# LRFDRFE32 register map
Vendor: Texas Instruments
Registers are 32-bit, access per field, reset 0x0 unless marked. A register's access mark holds for its fields unless they carry their own. Offsets are as the file gives them; [hi:lo] are bit positions; {n}, {i} and the like mark numbered series; 'fields as' and 'values as' point back to an identical list.

## LRFDRFE32 (part 2 of 2)
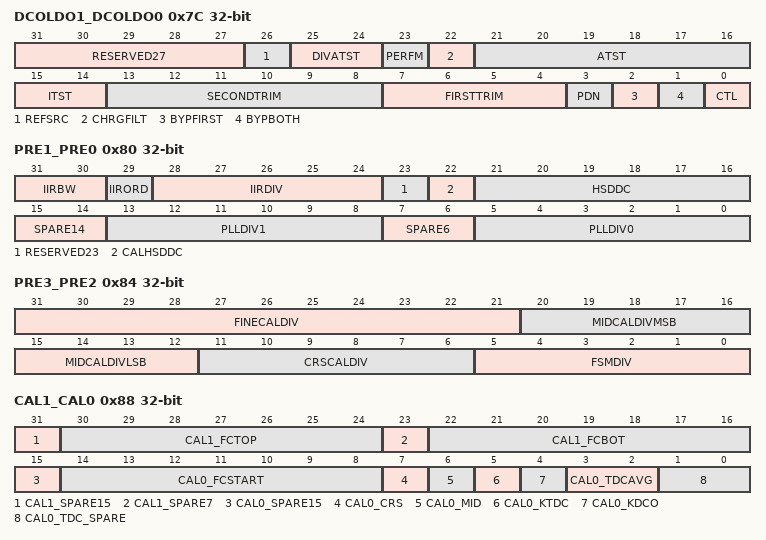
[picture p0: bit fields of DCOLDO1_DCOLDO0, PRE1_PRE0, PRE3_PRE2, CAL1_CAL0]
0x7C DCOLDO1_DCOLDO0 — Internal. Only to be used through TI provided API.
  [31:27] RESERVED27 ro — Internal. Only to be used through TI provided API.
  [26] REFSRC rw — Internal. Only to be used through TI provided API.
    1=BAW (Internal. Only to be used through TI provided API.); 0=XTAL (Internal. Only to be used through TI provided API.)
  [25:24] DIVATST rw — Internal. Only to be used through TI provided API.
    3=ONES (Internal. Only to be used through TI provided API.); 0=ZEROS (Internal. Only to be used through TI provided API.)
  [23] PERFM rw — Internal. Only to be used through TI provided API.
    1=EN (Internal. Only to be used through TI provided API.); 0=DIS (Internal. Only to be used through TI provided API.)
  [22] CHRGFILT rw — Internal. Only to be used through TI provided API.
    values as PERFM
  [21:16] ATST rw — Internal. Only to be used through TI provided API.
    32=VSSANA (Internal. Only to be used through TI provided API.); 1=FIRST_OUT (Internal. Only to be used through TI provided API.); 0=LDO_OUT (Internal. Only to be used through TI provided API.)
  [15:14] ITST rw — Internal. Only to be used through TI provided API.
    3=BOTH (Internal. Only to be used through TI provided API.); 2=SECOND (Internal. Only to be used through TI provided API.); 1=FIRST (Internal. Only to be used through TI provided API.); 0=DIS (Internal. Only to be used through TI provided API.)
  [13:8] SECONDTRIM rw — Internal. Only to be used through TI provided API.
    63=ONES (Internal. Only to be used through TI provided API.); 0=ZEROS (Internal. Only to be used through TI provided API.)
  [7:4] FIRSTTRIM rw — Internal. Only to be used through TI provided API.
    15=ONES (Internal. Only to be used through TI provided API.); 0=ZEROS (Internal. Only to be used through TI provided API.)
  [3] PDN rw — Internal. Only to be used through TI provided API.
    values as PERFM
  [2] BYPFIRST rw — Internal. Only to be used through TI provided API.
    values as PERFM
  [1] BYPBOTH rw — Internal. Only to be used through TI provided API.
    values as PERFM
  [0] CTL rw — Internal. Only to be used through TI provided API.
    values as PERFM
0x80 PRE1_PRE0 — Internal. Only to be used through TI provided API.
  [31:30] IIRBW rw — Internal. Only to be used through TI provided API.
    3=K16 (Internal. Only to be used through TI provided API.); 2=K8 (Internal. Only to be used through TI provided API.); 1=K4 (Internal. Only to be used through TI provided API.); 0=K2 (Internal. Only to be used through TI provided API.)
  [29] IIRORD rw — Internal. Only to be used through TI provided API.
    1=SECOND (Internal. Only to be used through TI provided API.); 0=FIRST (Internal. Only to be used through TI provided API.)
  [28:24] IIRDIV rw — Internal. Only to be used through TI provided API.
    31=ALLONES (Internal. Only to be used through TI provided API.); 0=ALLZEROS (Internal. Only to be used through TI provided API.)
  [23] RESERVED23 ro — Internal. Only to be used through TI provided API.
  [22] CALHSDDC rw — Internal. Only to be used through TI provided API.
    1=GATE (Internal. Only to be used through TI provided API.); 0=NOGATE (Internal. Only to be used through TI provided API.)
  [21:16] HSDDC rw — Internal. Only to be used through TI provided API.
    63=ALLONES (Internal. Only to be used through TI provided API.); 0=ALLZEROS (Internal. Only to be used through TI provided API.)
  [15:14] SPARE14 rw — Internal. Only to be used through TI provided API.
    3=ALLONES (Internal. Only to be used through TI provided API.); 0=ALLZEROS (Internal. Only to be used through TI provided API.)
  [13:8] PLLDIV1 rw — Internal. Only to be used through TI provided API.
    values as HSDDC
  [7:6] SPARE6 rw — Internal. Only to be used through TI provided API.
    values as SPARE14
  [5:0] PLLDIV0 rw — Internal. Only to be used through TI provided API.
    values as HSDDC
0x84 PRE3_PRE2 rw — Internal. Only to be used through TI provided API.
  [31:21] FINECALDIV — Internal. Only to be used through TI provided API.
    0x7FF=ALLONES (Internal. Only to be used through TI provided API.); 0=ALLZEROS (Internal. Only to be used through TI provided API.)
  [20:16] MIDCALDIVMSB — Internal. Only to be used through TI provided API.
    values as PRE1_PRE0.IIRDIV
  [15:12] MIDCALDIVLSB — Internal. Only to be used through TI provided API.
    15=ALLONES (Internal. Only to be used through TI provided API.); 0=ALLZEROS (Internal. Only to be used through TI provided API.)
  [11:6] CRSCALDIV — Internal. Only to be used through TI provided API.
    values as PRE1_PRE0.HSDDC
  [5:0] FSMDIV — Internal. Only to be used through TI provided API.
    values as PRE1_PRE0.HSDDC
0x88 CAL1_CAL0 rw — Internal. Only to be used through TI provided API.
  [31] CAL1_SPARE15 — Internal. Only to be used through TI provided API.
    1=ONE (Internal. Only to be used through TI provided API.); 0=ZERO (Internal. Only to be used through TI provided API.)
  [30:24] CAL1_FCTOP — Internal. Only to be used through TI provided API.
    127=ALLONES (Internal. Only to be used through TI provided API.); 0=ALLZEROS (Internal. Only to be used through TI provided API.)
  [23] CAL1_SPARE7 — Internal. Only to be used through TI provided API.
    values as CAL1_SPARE15
  [22:16] CAL1_FCBOT — Internal. Only to be used through TI provided API.
    values as CAL1_FCTOP
  [15] CAL0_SPARE15 — Internal. Only to be used through TI provided API.
    values as CAL1_SPARE15
  [14:8] CAL0_FCSTART — Internal. Only to be used through TI provided API.
    values as CAL1_FCTOP
  [7] CAL0_CRS — Internal. Only to be used through TI provided API.
    values as DCOLDO1_DCOLDO0.PERFM
  [6] CAL0_MID — Internal. Only to be used through TI provided API.
    values as DCOLDO1_DCOLDO0.PERFM
  [5] CAL0_KTDC — Internal. Only to be used through TI provided API.
    values as DCOLDO1_DCOLDO0.PERFM
  [4] CAL0_KDCO — Internal. Only to be used through TI provided API.
    values as DCOLDO1_DCOLDO0.PERFM
  [3:2] CAL0_TDCAVG — Internal. Only to be used through TI provided API.
    3=REPEAT_8_TIMES (Internal. Only to be used through TI provided API.); 2=REPEAT_4_TIMES (Internal. Only to be used through TI provided API.); 1=REPEAT_2_TIMES (Internal. Only to be used through TI provided API.); 0=REPEAT_1_TIME (Internal. Only to be used through TI provided API.)
  [1:0] CAL0_TDC_SPARE — Internal. Only to be used through TI provided API.
    values as PRE1_PRE0.SPARE14
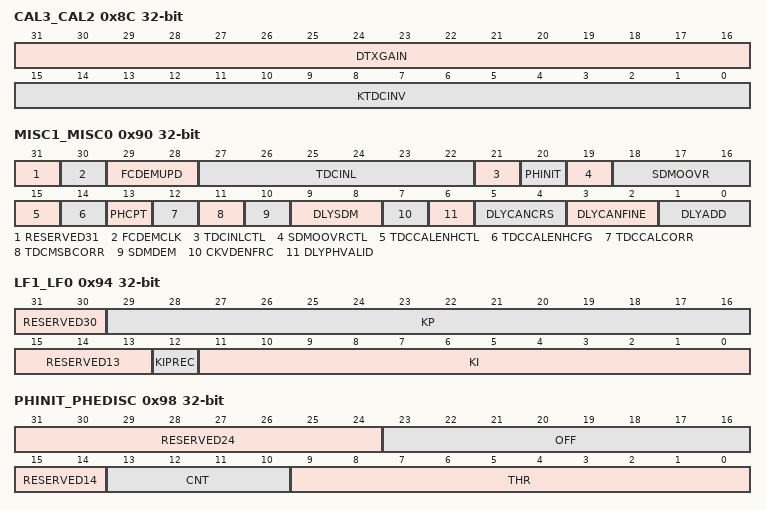
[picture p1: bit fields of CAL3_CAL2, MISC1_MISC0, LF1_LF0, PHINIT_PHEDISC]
0x8C CAL3_CAL2 rw — Internal. Only to be used through TI provided API.
  [31:16] DTXGAIN — Internal. Only to be used through TI provided API.
    0xFFFF=ALLONES (Internal. Only to be used through TI provided API.); 0=ALLZEROS (Internal. Only to be used through TI provided API.)
  [15:0] KTDCINV — Internal. Only to be used through TI provided API.
    values as DTXGAIN
0x90 MISC1_MISC0 — Internal. Only to be used through TI provided API.
  [31] RESERVED31 ro — Internal. Only to be used through TI provided API.
  [30] FCDEMCLK rw — Internal. Only to be used through TI provided API.
    1=CKVD64 (Internal. Only to be used through TI provided API.); 0=CKCD16 (Internal. Only to be used through TI provided API.)
  [29:28] FCDEMUPD rw — Internal. Only to be used through TI provided API.
    3=SDM_XOR_PH_ERR (Internal. Only to be used through TI provided API.); 2=SDM (Internal. Only to be used through TI provided API.); 1=PH_ERR (Internal. Only to be used through TI provided API.); 0=DEFAULT (Internal. Only to be used through TI provided API.)
  [27:22] TDCINL rw — Internal. Only to be used through TI provided API.
    values as DCOLDO1_DCOLDO0.SECONDTRIM
  [21] TDCINLCTL rw — Internal. Only to be used through TI provided API.
    values as DCOLDO1_DCOLDO0.PERFM
  [20] PHINIT rw — Internal. Only to be used through TI provided API.
    1=UNKNOWN (Internal. Only to be used through TI provided API.); 0=KNOWN (Internal. Only to be used through TI provided API.)
  [19] SDMOOVRCTL rw — Internal. Only to be used through TI provided API.
    values as DCOLDO1_DCOLDO0.PERFM
  [18:16] SDMOOVR rw — Internal. Only to be used through TI provided API.
    7=ALLONES (Internal. Only to be used through TI provided API.); 0=ALLZEROS (Internal. Only to be used through TI provided API.)
  [15] TDCCALENHCTL rw — Internal. Only to be used through TI provided API.
    values as DCOLDO1_DCOLDO0.PERFM
  [14] TDCCALENHCFG rw — Internal. Only to be used through TI provided API.
    1=MAXOFFSET (Internal. Only to be used through TI provided API.); 0=MINOFFSET (Internal. Only to be used through TI provided API.)
  [13] PHCPT rw — Internal. Only to be used through TI provided API.
    1=ASYNC (Internal. Only to be used through TI provided API.); 0=SYNC (Internal. Only to be used through TI provided API.)
  [12] TDCCALCORR rw — Internal. Only to be used through TI provided API.
    values as DCOLDO1_DCOLDO0.PERFM
  [11] TDCMSBCORR rw — Internal. Only to be used through TI provided API.
    values as DCOLDO1_DCOLDO0.PERFM
  [10] SDMDEM rw — Internal. Only to be used through TI provided API.
    values as DCOLDO1_DCOLDO0.PERFM
  [9:8] DLYSDM rw — Internal. Only to be used through TI provided API.
    {v}=CKVD16_{v}_PER (Internal. Only to be used through TI provided API.) (v=0..3)
  [7] CKVDENFRC rw — Internal. Only to be used through TI provided API.
    values as DCOLDO1_DCOLDO0.PERFM
  [6] DLYPHVALID rw — Internal. Only to be used through TI provided API.
    1=NOQUAL (Internal. Only to be used through TI provided API.); 0=QUAL (Internal. Only to be used through TI provided API.)
  [5:4] DLYCANCRS rw — Internal. Only to be used through TI provided API.
    {v}=CKVD64_{v}_PER (Internal. Only to be used through TI provided API.) (v=0..3)
  [3:2] DLYCANFINE rw — Internal. Only to be used through TI provided API.
    {v}=CKVD16_{v+1}_PER (Internal. Only to be used through TI provided API.) (v=0..3)
  [1:0] DLYADD rw — Internal. Only to be used through TI provided API.
    values as DLYCANCRS
0x94 LF1_LF0 — Internal. Only to be used through TI provided API.
  [31:30] RESERVED30 ro — Internal. Only to be used through TI provided API.
  [29:16] KP rw — Internal. Only to be used through TI provided API.
    0x3FFF=ALLONES (Internal. Only to be used through TI provided API.); 0=ALLZEROS (Internal. Only to be used through TI provided API.)
  [15:13] RESERVED13 ro — Internal. Only to be used through TI provided API.
  [12] KIPREC rw — Internal. Only to be used through TI provided API.
    1=HIGH (Internal. Only to be used through TI provided API.); 0=LOW (Internal. Only to be used through TI provided API.)
  [11:0] KI rw — Internal. Only to be used through TI provided API.
    0xFFF=ALLONES (Internal. Only to be used through TI provided API.); 0=ALLZEROS (Internal. Only to be used through TI provided API.)
0x98 PHINIT_PHEDISC — Internal. Only to be used through TI provided API.
  [31:24] RESERVED24 ro — Internal. Only to be used through TI provided API.
  [23:16] OFF rw — Internal. Only to be used through TI provided API.
    255=ALLONES (Internal. Only to be used through TI provided API.); 0=ALLZEROS (Internal. Only to be used through TI provided API.)
  [15:14] RESERVED14 ro — Internal. Only to be used through TI provided API.
  [13:10] CNT rw — Internal. Only to be used through TI provided API.
    values as PRE3_PRE2.MIDCALDIVLSB
  [9:0] THR rw — Internal. Only to be used through TI provided API.
    0x3FF=ALLONES (Internal. Only to be used through TI provided API.); 0=ALLZEROS (Internal. Only to be used through TI provided API.)
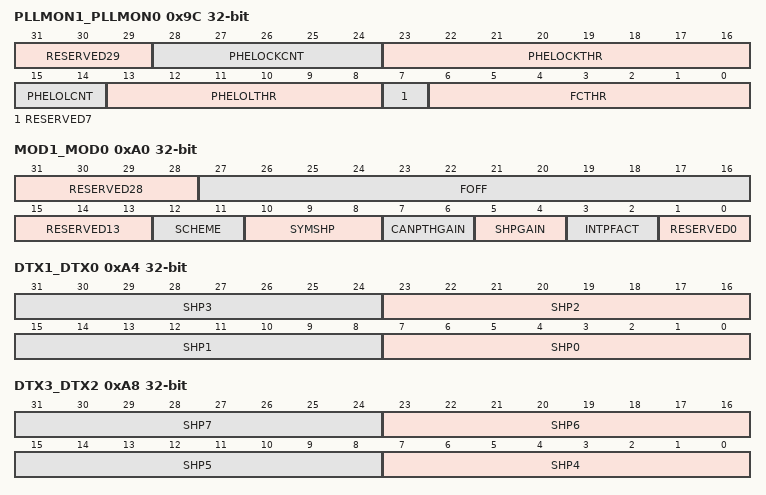
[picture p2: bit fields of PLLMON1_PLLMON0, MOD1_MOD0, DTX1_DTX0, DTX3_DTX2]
0x9C PLLMON1_PLLMON0 — Internal. Only to be used through TI provided API.
  [31:29] RESERVED29 ro — Internal. Only to be used through TI provided API.
  [28:24] PHELOCKCNT rw — Internal. Only to be used through TI provided API.
    values as PRE1_PRE0.IIRDIV
  [23:16] PHELOCKTHR rw — Internal. Only to be used through TI provided API.
    values as PHINIT_PHEDISC.OFF
  [15:14] PHELOLCNT rw — Internal. Only to be used through TI provided API.
    3=REFCLK_128_PER (Internal. Only to be used through TI provided API.); 2=REFCLK_64_PER (Internal. Only to be used through TI provided API.); 1=REFCLK_32_PER (Internal. Only to be used through TI provided API.); 0=REFCLK_16_PER (Internal. Only to be used through TI provided API.)
  [13:8] PHELOLTHR rw — Internal. Only to be used through TI provided API.
    values as PRE1_PRE0.HSDDC
  [7] RESERVED7 ro — Internal. Only to be used through TI provided API.
  [6:0] FCTHR rw — Internal. Only to be used through TI provided API.
    values as CAL1_CAL0.CAL1_FCTOP
0xA0 MOD1_MOD0 — Internal. Only to be used through TI provided API.
  [31:28] RESERVED28 ro — Internal. Only to be used through TI provided API.
  [27:16] FOFF rw — Internal. Only to be used through TI provided API.
    values as LF1_LF0.KI
  [15:13] RESERVED13 ro — Internal. Only to be used through TI provided API.
  [12:11] SCHEME rw — Internal. Only to be used through TI provided API.
    3=TWO_POINT_MOD_FRF (Internal. Only to be used through TI provided API.); 2=INLOOP_MOD_FRF (Internal. Only to be used through TI provided API.); 1=INLOOP_MOD_FREF (Internal. Only to be used through TI provided API.); 0=NC (Internal. Only to be used through TI provided API.)
  [10:8] SYMSHP rw — Internal. Only to be used through TI provided API.
    4=CHIRP (Internal. Only to be used through TI provided API.); 3=SHAPEDZIGBEE (Internal. Only to be used through TI provided API.); 2=PCWSPSK (Internal. Only to be used through TI provided API.); 1=ZIGBEE (Internal. Only to be used through TI provided API.); 0=SHAPEDFSK (Internal. Only to be used through TI provided API.)
  [7:6] CANPTHGAIN rw — Internal. Only to be used through TI provided API.
    {v}=TWO_POW_M_{v+15} (Internal. Only to be used through TI provided API.) (v=0..3)
  [5:4] SHPGAIN rw — Internal. Only to be used through TI provided API.
    3=X8 (Internal. Only to be used through TI provided API.); 2=X4 (Internal. Only to be used through TI provided API.); 1=X2 (Internal. Only to be used through TI provided API.); 0=Internal. Only to be used through TI provided API.
  [3:2] INTPFACT rw — Internal. Only to be used through TI provided API.
    3=ILLEGAL1 (Internal. Only to be used through TI provided API.); 2=INTP_BY_32 (Internal. Only to be used through TI provided API.); 1=INTP_BY_16 (Internal. Only to be used through TI provided API.); 0=ILLEGAL0 (Internal. Only to be used through TI provided API.)
  [1:0] RESERVED0 ro — Internal. Only to be used through TI provided API.
0xA4 DTX1_DTX0 rw — Internal. Only to be used through TI provided API.
  [all] fields
    values as PHINIT_PHEDISC.OFF
  [8n+7:8n] SHP{n} (n=0..3) — Internal. Only to be used through TI provided API.
0xA8 DTX3_DTX2 rw — Internal. Only to be used through TI provided API.
  [all] fields
    values as PHINIT_PHEDISC.OFF
  [8n-25:8n-32] SHP{n} (n=4..7) — Internal. Only to be used through TI provided API.
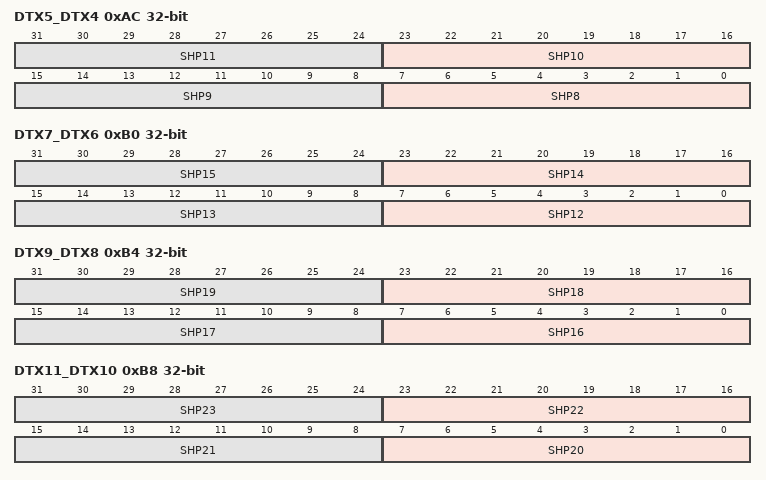
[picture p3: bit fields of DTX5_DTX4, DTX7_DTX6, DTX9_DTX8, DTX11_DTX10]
0xAC DTX5_DTX4 rw — Internal. Only to be used through TI provided API.
  [all] fields
    values as PHINIT_PHEDISC.OFF
  [8n-57:8n-64] SHP{n} (n=8..11) — Internal. Only to be used through TI provided API.
0xB0 DTX7_DTX6 rw — Internal. Only to be used through TI provided API.
  [all] fields
    values as PHINIT_PHEDISC.OFF
  [8n-89:8n-96] SHP{n} (n=12..15) — Internal. Only to be used through TI provided API.
0xB4 DTX9_DTX8 rw — Internal. Only to be used through TI provided API.
  [all] fields
    values as PHINIT_PHEDISC.OFF
  [8n-121:8n-128] SHP{n} (n=16..19) — Internal. Only to be used through TI provided API.
0xB8 DTX11_DTX10 rw — Internal. Only to be used through TI provided API.
  [all] fields
    values as PHINIT_PHEDISC.OFF
  [8n-153:8n-160] SHP{n} (n=20..23) — Internal. Only to be used through TI provided API.
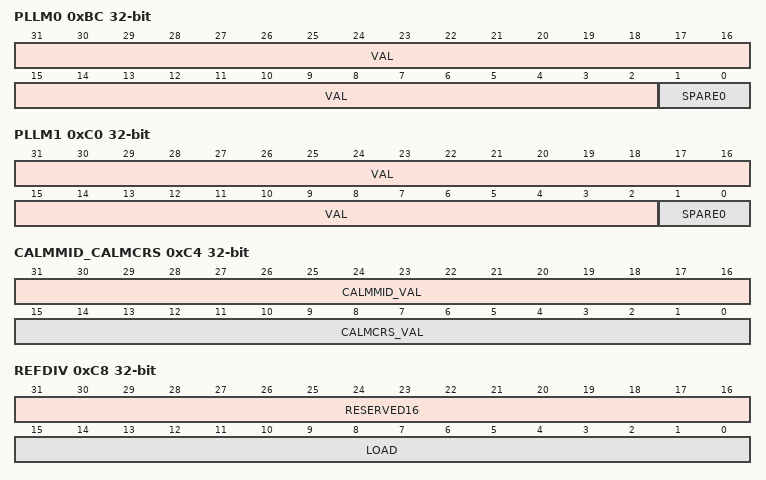
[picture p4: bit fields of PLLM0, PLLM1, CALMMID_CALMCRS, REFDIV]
0xBC PLLM0 rw — Internal. Only to be used through TI provided API.
  [31:2] VAL — Internal. Only to be used through TI provided API.
    values as LF1_LF0.KP
  [1:0] SPARE0 — Internal. Only to be used through TI provided API.
    values as PRE1_PRE0.SPARE14
0xC0 PLLM1 rw — Internal. Only to be used through TI provided API.
  fields as PLLM0
0xC4 CALMMID_CALMCRS rw — Internal. Only to be used through TI provided API.
  [31:16] CALMMID_VAL — Internal. Only to be used through TI provided API.
    values as CAL3_CAL2.DTXGAIN
  [15:0] CALMCRS_VAL — Internal. Only to be used through TI provided API.
    values as CAL3_CAL2.DTXGAIN
0xC8 REFDIV — Internal. Only to be used through TI provided API.
  [31:16] RESERVED16 ro — Internal. Only to be used through TI provided API.
  [15:0] LOAD rw — Internal. Only to be used through TI provided API.
    values as CAL3_CAL2.DTXGAIN
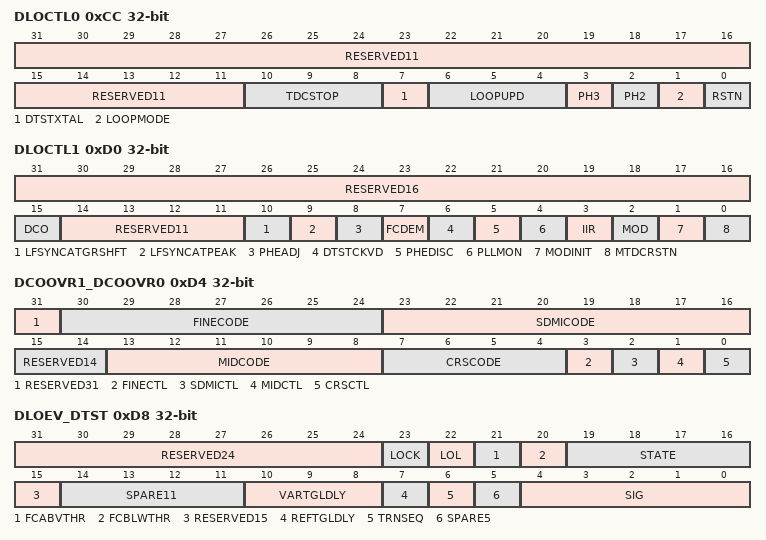
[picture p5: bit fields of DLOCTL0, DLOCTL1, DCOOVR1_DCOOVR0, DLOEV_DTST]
0xCC DLOCTL0 — Internal. Only to be used through TI provided API.
  [31:11] RESERVED11 ro — Internal. Only to be used through TI provided API.
  [10:8] TDCSTOP rw — Internal. Only to be used through TI provided API.
    1=OPEN (Internal. Only to be used through TI provided API.); 0=CLOSED (Internal. Only to be used through TI provided API.)
  [7] DTSTXTAL rw — Internal. Only to be used through TI provided API.
    values as CAL1_CAL0.CAL1_SPARE15
  [6:4] LOOPUPD rw — Internal. Only to be used through TI provided API.
    1=ALT (Internal. Only to be used through TI provided API.); 0=DEF (Internal. Only to be used through TI provided API.)
  [3] PH3 rw — Internal. Only to be used through TI provided API.
    1=START (Internal. Only to be used through TI provided API.); 0=HALT (Internal. Only to be used through TI provided API.)
  [2] PH2 rw — Internal. Only to be used through TI provided API.
    values as PH3
  [1] LOOPMODE rw — Internal. Only to be used through TI provided API.
    values as TDCSTOP
  [0] RSTN rw — Internal. Only to be used through TI provided API.
    1=ACTIVE (Internal. Only to be used through TI provided API.); 0=RESET (Internal. Only to be used through TI provided API.)
0xD0 DLOCTL1 — Internal. Only to be used through TI provided API.
  [31:16] RESERVED16 ro — Internal. Only to be used through TI provided API.
  [15] DCO rw — Internal. Only to be used through TI provided API.
    values as DCOLDO1_DCOLDO0.PERFM
  [14:11] RESERVED11 ro — Internal. Only to be used through TI provided API.
  [10] LFSYNCATGRSHFT rw — Internal. Only to be used through TI provided API.
    values as DCOLDO1_DCOLDO0.PERFM
  [9] LFSYNCATPEAK rw — Internal. Only to be used through TI provided API.
    values as DCOLDO1_DCOLDO0.PERFM
  [8] PHEADJ rw — Internal. Only to be used through TI provided API.
    values as DCOLDO1_DCOLDO0.PERFM
  [7] FCDEM rw — Internal. Only to be used through TI provided API.
    values as DCOLDO1_DCOLDO0.PERFM
  [6] DTSTCKVD rw — Internal. Only to be used through TI provided API.
    values as CAL1_CAL0.CAL1_SPARE15
  [5] PHEDISC rw — Internal. Only to be used through TI provided API.
    values as DCOLDO1_DCOLDO0.PERFM
  [4] PLLMON rw — Internal. Only to be used through TI provided API.
    values as DCOLDO1_DCOLDO0.PERFM
  [3] IIR rw — Internal. Only to be used through TI provided API.
    values as DCOLDO1_DCOLDO0.PERFM
  [2] MOD rw — Internal. Only to be used through TI provided API.
    values as DCOLDO1_DCOLDO0.PERFM
  [1] MODINIT rw — Internal. Only to be used through TI provided API.
    1=ACTIVATE (Internal. Only to be used through TI provided API.); 0=DEACTIVATE (Internal. Only to be used through TI provided API.)
  [0] MTDCRSTN rw — Internal. Only to be used through TI provided API.
    values as DLOCTL0.RSTN
0xD4 DCOOVR1_DCOOVR0 — Internal. Only to be used through TI provided API.
  [31] RESERVED31 ro — Internal. Only to be used through TI provided API.
  [30:24] FINECODE rw — Internal. Only to be used through TI provided API.
    values as CAL1_CAL0.CAL1_FCTOP
  [23:16] SDMICODE rw — Internal. Only to be used through TI provided API.
    values as PHINIT_PHEDISC.OFF
  [15:14] RESERVED14 ro — Internal. Only to be used through TI provided API.
  [13:8] MIDCODE rw — Internal. Only to be used through TI provided API.
    values as PRE1_PRE0.HSDDC
  [7:4] CRSCODE rw — Internal. Only to be used through TI provided API.
    values as PRE3_PRE2.MIDCALDIVLSB
  [3] FINECTL rw — Internal. Only to be used through TI provided API.
    values as DCOLDO1_DCOLDO0.PERFM
  [2] SDMICTL rw — Internal. Only to be used through TI provided API.
    values as DCOLDO1_DCOLDO0.PERFM
  [1] MIDCTL rw — Internal. Only to be used through TI provided API.
    values as DCOLDO1_DCOLDO0.PERFM
  [0] CRSCTL rw — Internal. Only to be used through TI provided API.
    values as DCOLDO1_DCOLDO0.PERFM
0xD8 DLOEV_DTST — Internal. Only to be used through TI provided API.
  [31:24] RESERVED24 ro — Internal. Only to be used through TI provided API.
  [23] LOCK ro — Internal. Only to be used through TI provided API.
    values as CAL1_CAL0.CAL1_SPARE15
  [22] LOL ro — Internal. Only to be used through TI provided API.
    values as CAL1_CAL0.CAL1_SPARE15
  [21] FCABVTHR ro — Internal. Only to be used through TI provided API.
    values as CAL1_CAL0.CAL1_SPARE15
  [20] FCBLWTHR ro — Internal. Only to be used through TI provided API.
    values as CAL1_CAL0.CAL1_SPARE15
  [19:16] STATE ro — Internal. Only to be used through TI provided API.
    values as PRE3_PRE2.MIDCALDIVLSB
  [15] RESERVED15 ro — Internal. Only to be used through TI provided API.
  [14:11] SPARE11 rw — Internal. Only to be used through TI provided API.
    values as PRE3_PRE2.MIDCALDIVLSB
  [10:8] VARTGLDLY rw — Internal. Only to be used through TI provided API.
    {v}=CLK_{v}_PER (Internal. Only to be used through TI provided API.) (v=0..7)
  [7] REFTGLDLY rw — Internal. Only to be used through TI provided API.
    1=CLK_1_PER (Internal. Only to be used through TI provided API.); 0=CLK_0_PER (Internal. Only to be used through TI provided API.)
  [6] TRNSEQ rw — Internal. Only to be used through TI provided API.
    values as DCOLDO1_DCOLDO0.PERFM
  [5] SPARE5 rw — Internal. Only to be used through TI provided API.
    values as CAL1_CAL0.CAL1_SPARE15
  [4:0] SIG rw — Internal. Only to be used through TI provided API.
    31=VAR_NC_15 (Internal. Only to be used through TI provided API.); 30=VAR_NC_14 (Internal. Only to be used through TI provided API.); 29=VAR_NC_13 (Internal. Only to be used through TI provided API.); 28=VAR_FCPHELFSYNC (Internal. Only to be used through TI provided API.); 27=VAR_FCPHE (Internal. Only to be used through TI provided API.); 26=VAR_LOOP_UPD_FINECODE (Internal. Only to be used through TI provided API.); 25=VAR_LOCK_FINECODE (Internal. Only to be used through TI provided API.); 24=VAR_MPX_CAN (Internal. Only to be used through TI provided API.); 23=VAR_TDCSTOP_STATUS_TDC (Internal. Only to be used through TI provided API.); 22=VAR_TDCSTOP_PHERR (Internal. Only to be used through TI provided API.); 21=VAR_PH_COMP_PHERR_TDCSTOP (Internal. Only to be used through TI provided API.); 20=VAR_PH_TDCCORR (Internal. Only to be used through TI provided API.); 19=VAR_PH_RAW (Internal. Only to be used through TI provided API.); 18=VAR_PHERR_LOWER (Internal. Only to be used through TI provided API.); 17=VAR_PHERR_UPPER (Internal. Only to be used through TI provided API.); 16=VAR_NC_0 (Internal. Only to be used through TI provided API.); {v}=REF_NC_{v} (Internal. Only to be used through TI provided API.) (v=3..15); 2=REF_FERR_MAG (Internal. Only to be used through TI provided API.); 1=REF_FSMCAL (Internal. Only to be used through TI provided API.); 0=REF_NC_0 (Internal. Only to be used through TI provided API.)
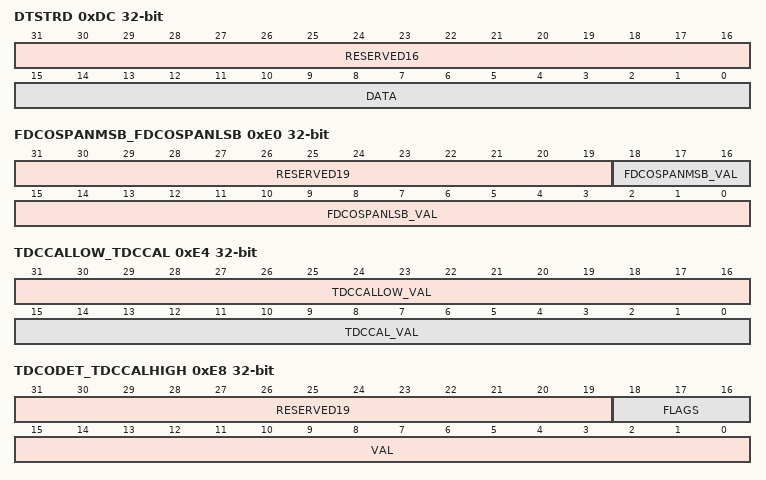
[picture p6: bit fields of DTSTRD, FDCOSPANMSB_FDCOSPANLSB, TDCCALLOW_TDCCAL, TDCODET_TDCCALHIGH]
0xDC DTSTRD ro — Internal. Only to be used through TI provided API.
  [31:16] RESERVED16 — Internal. Only to be used through TI provided API.
  [15:0] DATA — Internal. Only to be used through TI provided API.
    values as CAL3_CAL2.DTXGAIN
0xE0 FDCOSPANMSB_FDCOSPANLSB ro — Internal. Only to be used through TI provided API.
  [31:19] RESERVED19 — Internal. Only to be used through TI provided API.
  [18:16] FDCOSPANMSB_VAL — Internal. Only to be used through TI provided API.
    values as MISC1_MISC0.SDMOOVR
  [15:0] FDCOSPANLSB_VAL — Internal. Only to be used through TI provided API.
    values as CAL3_CAL2.DTXGAIN
0xE4 TDCCALLOW_TDCCAL ro — Internal. Only to be used through TI provided API.
  [31:16] TDCCALLOW_VAL — Internal. Only to be used through TI provided API.
    values as CAL3_CAL2.DTXGAIN
  [15:0] TDCCAL_VAL — Internal. Only to be used through TI provided API.
    values as CAL3_CAL2.DTXGAIN
0xE8 TDCODET_TDCCALHIGH ro — Internal. Only to be used through TI provided API.
  [31:19] RESERVED19 — Internal. Only to be used through TI provided API.
  [18:16] FLAGS — Internal. Only to be used through TI provided API.
    values as MISC1_MISC0.SDMOOVR
  [15:0] VAL — Internal. Only to be used through TI provided API.
    values as CAL3_CAL2.DTXGAIN
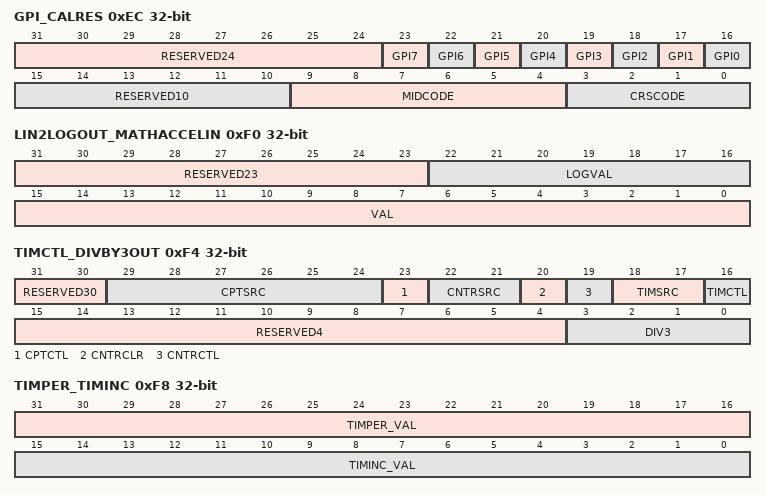
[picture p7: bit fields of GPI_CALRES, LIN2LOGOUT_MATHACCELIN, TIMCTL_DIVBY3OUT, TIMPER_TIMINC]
0xEC GPI_CALRES ro — Internal. Only to be used through TI provided API.
  [31:24] RESERVED24 — Internal. Only to be used through TI provided API.
  [n+16] GPI{n} (n=0..7) — Internal. Only to be used through TI provided API.
    values as CAL1_CAL0.CAL1_SPARE15
  [15:10] RESERVED10 — Internal. Only to be used through TI provided API.
  [9:4] MIDCODE — Internal. Only to be used through TI provided API.
    values as PRE1_PRE0.HSDDC
  [3:0] CRSCODE — Internal. Only to be used through TI provided API.
    values as PRE3_PRE2.MIDCALDIVLSB
0xF0 LIN2LOGOUT_MATHACCELIN — Internal. Only to be used through TI provided API.
  [31:23] RESERVED23 ro — Internal. Only to be used through TI provided API.
  [22:16] LOGVAL ro — Internal. Only to be used through TI provided API.
    values as CAL1_CAL0.CAL1_FCTOP
  [15:0] VAL rw — Internal. Only to be used through TI provided API.
    values as CAL3_CAL2.DTXGAIN
0xF4 TIMCTL_DIVBY3OUT — Internal. Only to be used through TI provided API.
  [31:30] RESERVED30 ro — Internal. Only to be used through TI provided API.
  [29:24] CPTSRC rw — Internal. Only to be used through TI provided API.
    values as PRE1_PRE0.HSDDC
  [23] CPTCTL rw — Internal. Only to be used through TI provided API.
    values as DCOLDO1_DCOLDO0.PERFM
  [22:21] CNTRSRC rw — Internal. Only to be used through TI provided API.
    3=FREF (Internal. Only to be used through TI provided API.); 2=MAGN1 (Internal. Only to be used through TI provided API.); 1=MAGN0 (Internal. Only to be used through TI provided API.); 0=CLK (Internal. Only to be used through TI provided API.)
  [20] CNTRCLR rw — Internal. Only to be used through TI provided API.
    values as CAL1_CAL0.CAL1_SPARE15
  [19] CNTRCTL rw — Internal. Only to be used through TI provided API.
    values as DCOLDO1_DCOLDO0.PERFM
  [18:17] TIMSRC rw — Internal. Only to be used through TI provided API.
    values as CNTRSRC
  [16] TIMCTL rw — Internal. Only to be used through TI provided API.
    values as DCOLDO1_DCOLDO0.PERFM
  [15:4] RESERVED4 ro — Internal. Only to be used through TI provided API.
  [3:0] DIV3 ro — Internal. Only to be used through TI provided API.
    values as PRE3_PRE2.MIDCALDIVLSB
0xF8 TIMPER_TIMINC rw — Internal. Only to be used through TI provided API.
  [31:16] TIMPER_VAL — Internal. Only to be used through TI provided API.
    values as CAL3_CAL2.DTXGAIN
  [15:0] TIMINC_VAL — Internal. Only to be used through TI provided API.
    values as CAL3_CAL2.DTXGAIN
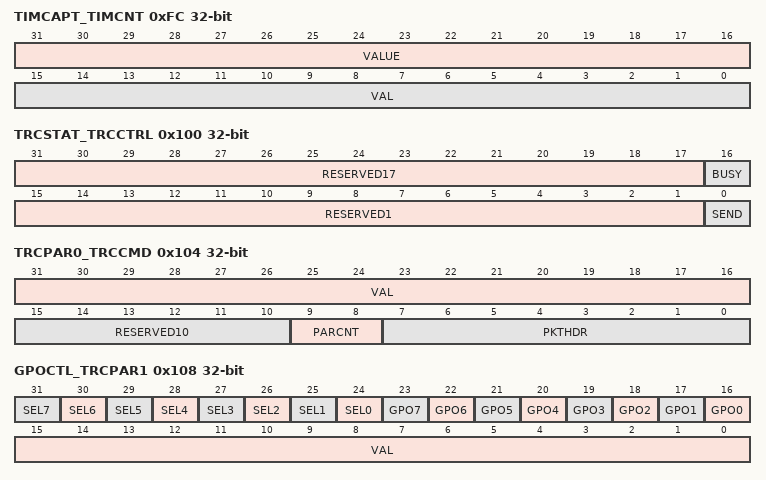
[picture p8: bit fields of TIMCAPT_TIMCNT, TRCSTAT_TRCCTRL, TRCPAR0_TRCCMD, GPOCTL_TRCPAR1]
0xFC TIMCAPT_TIMCNT ro — Internal. Only to be used through TI provided API.
  [31:16] VALUE — Internal. Only to be used through TI provided API.
    values as CAL3_CAL2.DTXGAIN
  [15:0] VAL — Internal. Only to be used through TI provided API.
    values as CAL3_CAL2.DTXGAIN
0x100 TRCSTAT_TRCCTRL — Internal. Only to be used through TI provided API.
  [31:17] RESERVED17 ro — Internal. Only to be used through TI provided API.
  [16] BUSY ro — Internal. Only to be used through TI provided API.
    values as CAL1_CAL0.CAL1_SPARE15
  [15:1] RESERVED1 ro — Internal. Only to be used through TI provided API.
  [0] SEND wo — Internal. Only to be used through TI provided API.
    values as CAL1_CAL0.CAL1_SPARE15
0x104 TRCPAR0_TRCCMD — Internal. Only to be used through TI provided API.
  [31:16] VAL rw — Internal. Only to be used through TI provided API.
    values as CAL3_CAL2.DTXGAIN
  [15:10] RESERVED10 ro — Internal. Only to be used through TI provided API.
  [9:8] PARCNT rw — Internal. Only to be used through TI provided API.
    values as PRE1_PRE0.SPARE14
  [7:0] PKTHDR rw — Internal. Only to be used through TI provided API.
    values as PHINIT_PHEDISC.OFF
0x108 GPOCTL_TRCPAR1 rw — Internal. Only to be used through TI provided API.
  [n+24] SEL{n} (n=0..7) — Internal. Only to be used through TI provided API.
    1=HW (Internal. Only to be used through TI provided API.); 0=SW (Internal. Only to be used through TI provided API.)
  [n+16] GPO{n} (n=0..7) — Internal. Only to be used through TI provided API.
    values as CAL1_CAL0.CAL1_SPARE15
  [15:0] VAL — Internal. Only to be used through TI provided API.
    values as CAL3_CAL2.DTXGAIN
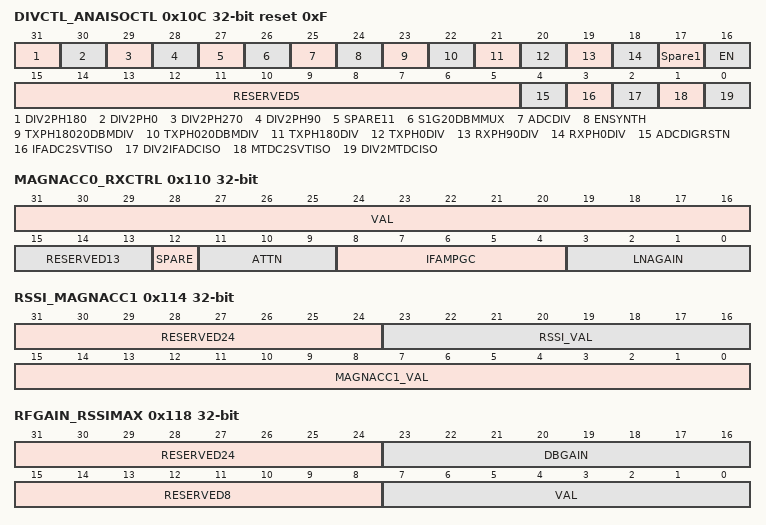
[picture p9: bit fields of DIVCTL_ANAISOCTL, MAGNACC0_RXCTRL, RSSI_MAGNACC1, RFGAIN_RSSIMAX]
0x10C DIVCTL_ANAISOCTL reset 0xF — Internal. Only to be used through TI provided API.
  [31] DIV2PH180 rw — Internal. Only to be used through TI provided API.
    values as DCOLDO1_DCOLDO0.PERFM
  [30] DIV2PH0 rw — Internal. Only to be used through TI provided API.
    values as DCOLDO1_DCOLDO0.PERFM
  [29] DIV2PH270 rw — Internal. Only to be used through TI provided API.
    values as DCOLDO1_DCOLDO0.PERFM
  [28] DIV2PH90 rw — Internal. Only to be used through TI provided API.
    values as DCOLDO1_DCOLDO0.PERFM
  [27] SPARE11 rw — Internal. Only to be used through TI provided API.
    values as CAL1_CAL0.CAL1_SPARE15
  [26] S1G20DBMMUX rw — Internal. Only to be used through TI provided API.
    1=DISABLE (Internal. Only to be used through TI provided API.); 0=ENABLEN (Internal. Only to be used through TI provided API.)
  [25] ADCDIV rw — Internal. Only to be used through TI provided API.
    values as DCOLDO1_DCOLDO0.PERFM
  [24] ENSYNTH rw — Internal. Only to be used through TI provided API.
    values as DCOLDO1_DCOLDO0.PERFM
  [23] TXPH18020DBMDIV rw — Internal. Only to be used through TI provided API.
    values as DCOLDO1_DCOLDO0.PERFM
  [22] TXPH020DBMDIV rw — Internal. Only to be used through TI provided API.
    values as DCOLDO1_DCOLDO0.PERFM
  [21] TXPH180DIV rw — Internal. Only to be used through TI provided API.
    values as DCOLDO1_DCOLDO0.PERFM
  [20] TXPH0DIV rw — Internal. Only to be used through TI provided API.
    values as DCOLDO1_DCOLDO0.PERFM
  [19] RXPH90DIV rw — Internal. Only to be used through TI provided API.
    values as DCOLDO1_DCOLDO0.PERFM
  [18] RXPH0DIV rw — Internal. Only to be used through TI provided API.
    values as DCOLDO1_DCOLDO0.PERFM
  [17] Spare1 rw — Internal. Only to be used through TI provided API.
    values as CAL1_CAL0.CAL1_SPARE15
  [16] EN rw — Internal. Only to be used through TI provided API.
    1=ON (Internal. Only to be used through TI provided API.); 0=OFF (Internal. Only to be used through TI provided API.)
  [15:5] RESERVED5 ro — Internal. Only to be used through TI provided API.
  [4] ADCDIGRSTN rw — Internal. Only to be used through TI provided API.
    values as DLOCTL0.RSTN
  [3] IFADC2SVTISO rw — Internal. Only to be used through TI provided API.
    1=ISOLATE (Internal. Only to be used through TI provided API.); 0=CONNECT (Internal. Only to be used through TI provided API.)
  [2] DIV2IFADCISO rw — Internal. Only to be used through TI provided API.
    values as IFADC2SVTISO
  [1] MTDC2SVTISO rw — Internal. Only to be used through TI provided API.
    values as IFADC2SVTISO
  [0] DIV2MTDCISO rw — Internal. Only to be used through TI provided API.
    values as IFADC2SVTISO
0x110 MAGNACC0_RXCTRL — Internal. Only to be used through TI provided API.
  [31:16] VAL ro — Internal. Only to be used through TI provided API.
    values as CAL3_CAL2.DTXGAIN
  [15:13] RESERVED13 ro — Internal. Only to be used through TI provided API.
  [12] SPARE rw — Internal. Only to be used through TI provided API.
    values as CAL1_CAL0.CAL1_SPARE15
  [11:9] ATTN rw — Internal. Only to be used through TI provided API.
    7=_21DB (Internal. Only to be used through TI provided API.); 6=_18DB (Internal. Only to be used through TI provided API.); 5=_15DB (Internal. Only to be used through TI provided API.); 4=_12DB (Internal. Only to be used through TI provided API.); 3=_9DB (Internal. Only to be used through TI provided API.); 2=_6DB (Internal. Only to be used through TI provided API.); 1=_3DB (Internal. Only to be used through TI provided API.); 0=NOATT (Internal. Only to be used through TI provided API.)
  [8:4] IFAMPGC rw — Internal. Only to be used through TI provided API.
    31=MAX (Internal. Only to be used through TI provided API.); 15=MIN3DB (Internal. Only to be used through TI provided API.); 7=MIN6DB (Internal. Only to be used through TI provided API.); 3=MIN9DB (Internal. Only to be used through TI provided API.); 1=MIN12DB (Internal. Only to be used through TI provided API.); 0=MIN15DB (Internal. Only to be used through TI provided API.)
  [3:0] LNAGAIN rw — Internal. Only to be used through TI provided API.
    15=MAX (Internal. Only to be used through TI provided API.); 7=MIN3DB (Internal. Only to be used through TI provided API.); 3=MIN6DB (Internal. Only to be used through TI provided API.); 1=MIN9DB (Internal. Only to be used through TI provided API.); 0=MIN12DB (Internal. Only to be used through TI provided API.)
0x114 RSSI_MAGNACC1 — Internal. Only to be used through TI provided API.
  [31:24] RESERVED24 ro — Internal. Only to be used through TI provided API.
  [23:16] RSSI_VAL rw — Internal. Only to be used through TI provided API.
    values as PHINIT_PHEDISC.OFF
  [15:0] MAGNACC1_VAL ro — Internal. Only to be used through TI provided API.
    values as CAL3_CAL2.DTXGAIN
0x118 RFGAIN_RSSIMAX — Internal. Only to be used through TI provided API.
  [31:24] RESERVED24 ro — Internal. Only to be used through TI provided API.
  [23:16] DBGAIN rw — Internal. Only to be used through TI provided API.
    values as PHINIT_PHEDISC.OFF
  [15:8] RESERVED8 ro — Internal. Only to be used through TI provided API.
  [7:0] VAL rw — Internal. Only to be used through TI provided API.
    values as PHINIT_PHEDISC.OFF
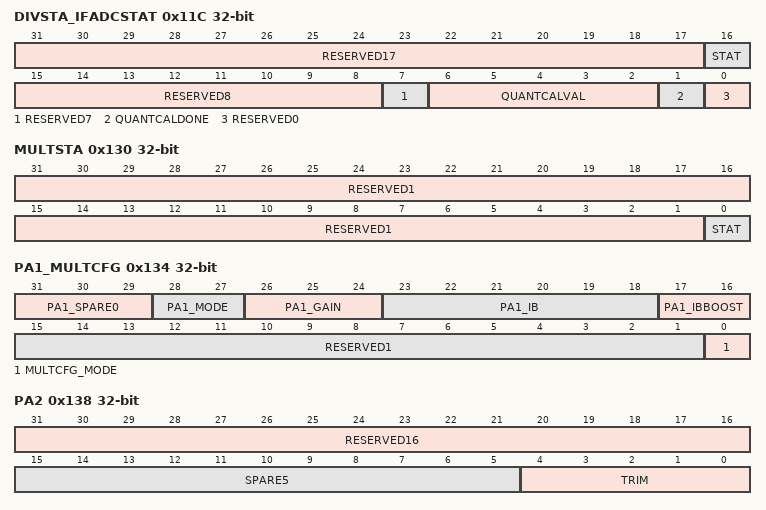
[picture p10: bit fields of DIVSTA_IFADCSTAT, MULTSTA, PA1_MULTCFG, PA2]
0x11C DIVSTA_IFADCSTAT ro — Internal. Only to be used through TI provided API.
  [31:17] RESERVED17 — Internal. Only to be used through TI provided API.
  [16] STAT — Internal. Only to be used through TI provided API.
    1=BUSY (Internal. Only to be used through TI provided API.); 0=IDLE (Internal. Only to be used through TI provided API.)
  [15:8] RESERVED8 — Internal. Only to be used through TI provided API.
  [7] RESERVED7 — Internal. Only to be used through TI provided API.
    values as CAL1_CAL0.CAL1_SPARE15
  [6:2] QUANTCALVAL — Internal. Only to be used through TI provided API.
    1=COMP1 (Internal. Only to be used through TI provided API.); 0=COMP0 (Internal. Only to be used through TI provided API.)
  [1] QUANTCALDONE — Internal. Only to be used through TI provided API.
    1=READY (Internal. Only to be used through TI provided API.); 0=NOT_READY (Internal. Only to be used through TI provided API.)
  [0] RESERVED0 — Internal. Only to be used through TI provided API.
    values as CAL1_CAL0.CAL1_SPARE15
0x120 DIVIDEND wo — Internal. Only to be used through TI provided API.
  [31:0] VAL
    values as CAL3_CAL2.DTXGAIN
0x124 DIVISOR rw — Internal. Only to be used through TI provided API.
  fields as DIVIDEND
0x128 QUOTIENT ro — Internal. Only to be used through TI provided API.
  fields as DIVIDEND
0x12C PRODUCT ro — Internal. Only to be used through TI provided API.
  fields as DIVIDEND
0x130 MULTSTA ro — Internal. Only to be used through TI provided API.
  [31:1] RESERVED1 — Internal. Only to be used through TI provided API.
  [0] STAT — Internal. Only to be used through TI provided API.
    values as DIVSTA_IFADCSTAT.STAT
0x134 PA1_MULTCFG — Internal. Only to be used through TI provided API.
  [31:29] PA1_SPARE0 rw — Internal. Only to be used through TI provided API.
    7=MAX (Internal. Only to be used through TI provided API.); 0=MIN (Internal. Only to be used through TI provided API.)
  [28:27] PA1_MODE rw — Internal. Only to be used through TI provided API.
    3=DBM20 (Internal. Only to be used through TI provided API.); 2=DBM12 (Internal. Only to be used through TI provided API.); 1=DBM5 (Internal. Only to be used through TI provided API.); 0=DBM0 (Internal. Only to be used through TI provided API.)
  [26:24] PA1_GAIN rw — Internal. Only to be used through TI provided API.
    values as PA1_SPARE0
  [23:18] PA1_IB rw — Internal. Only to be used through TI provided API.
    63=MAX (Internal. Only to be used through TI provided API.); 0=MIN (Internal. Only to be used through TI provided API.)
  [17:16] PA1_IBBOOST rw — Internal. Only to be used through TI provided API.
    3=MAX (Internal. Only to be used through TI provided API.); 0=MIN (Internal. Only to be used through TI provided API.)
  [15:1] RESERVED1 ro — Internal. Only to be used through TI provided API.
  [0] MULTCFG_MODE rw — Internal. Only to be used through TI provided API.
    1=SIGNED (Internal. Only to be used through TI provided API.); 0=UNSIGNED (Internal. Only to be used through TI provided API.)
0x138 PA2 — Internal. Only to be used through TI provided API.
  [31:16] RESERVED16 ro — Internal. Only to be used through TI provided API.
  [15:5] SPARE5 rw — Internal. Only to be used through TI provided API.
    0x7FF=MAX (Internal. Only to be used through TI provided API.); 0=MIN (Internal. Only to be used through TI provided API.)
  [4:0] TRIM rw — Internal. Only to be used through TI provided API.
    31=MAX (Internal. Only to be used through TI provided API.); 0=MIN (Internal. Only to be used through TI provided API.)
